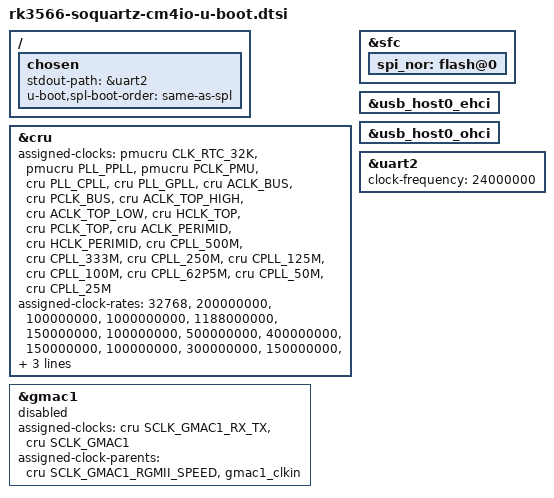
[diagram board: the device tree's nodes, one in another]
// SPDX-License-Identifier: GPL-2.0+
/*
 * (C) Copyright 2021 Rockchip Electronics Co., Ltd
 */

#include "rk3568-u-boot.dtsi"

/ {
	chosen {
		stdout-path = &uart2;
		u-boot,spl-boot-order = "same-as-spl", &spi_nor, &sdmmc0, &sdhci;
	};
};

&cru {
	assigned-clocks =
			<&pmucru CLK_RTC_32K>,
			<&pmucru PLL_PPLL>,
			<&pmucru PCLK_PMU>, <&cru PLL_CPLL>,
			<&cru PLL_GPLL>,
			<&cru ACLK_BUS>, <&cru PCLK_BUS>,
			<&cru ACLK_TOP_HIGH>, <&cru ACLK_TOP_LOW>,
			<&cru HCLK_TOP>, <&cru PCLK_TOP>,
			<&cru ACLK_PERIMID>, <&cru HCLK_PERIMID>,
			<&cru CPLL_500M>, <&cru CPLL_333M>,
			<&cru CPLL_250M>, <&cru CPLL_125M>,
			<&cru CPLL_100M>, <&cru CPLL_62P5M>,
			<&cru CPLL_50M>, <&cru CPLL_25M>;
	assigned-clock-rates =
			<32768>,
			<200000000>,
			<100000000>, <1000000000>,
			<1188000000>,
			<150000000>, <100000000>,
			<500000000>, <400000000>,
			<150000000>, <100000000>,
			<300000000>, <150000000>,
			<500000000>, <333333333>,
			<250000000>, <125000000>,
			<100000000>, <62500000>,
			<50000000>, <25000000>;
	assigned-clock-parents =
			<&pmucru CLK_RTC32K_FRAC>;
};

&gmac1 {
	assigned-clocks = <&cru SCLK_GMAC1_RX_TX>, <&cru SCLK_GMAC1>;
	assigned-clock-parents = <&cru SCLK_GMAC1_RGMII_SPEED>, <&gmac1_clkin>;
	status = "disabled";
};

&sfc {
	spi_nor: flash@0 {
		u-boot,dm-spl;
	};
};

&usb_host0_ehci {
//	vbus-supply = <&vcc5v0_usb30_host>;
};

&usb_host0_ohci {
//	vbus-supply = <&vcc5v0_usb30_host>;
};

&uart2 {
	clock-frequency = <24000000>;
	u-boot,dm-spl;
	status = "okay";
};
